# Template register map
Vendor: VendorName Co.Ltd; Series: SeriesName; File version: 1.2
CPU: CM7 r0p1, little endian, MPU, FPU, 4 interrupt priority bits
Registers are 32-bit, read-write, no defined reset value unless marked. A register's access mark holds for its fields unless they carry their own. Offsets are from the block's base; [hi:lo] are bit positions.

## CMPSS1 — Comparer Subsystem 1
Base 0x4001B000
Same registers: CMPSS2 0x4001B100, CMPSS3 0x4001B200, CMPSS4 0x4001B300, CMPSS5 0x4001B400, CMPSS6 0x4001B500, CMPSS7 0x4001B600, CMPSS8 0x4001B700
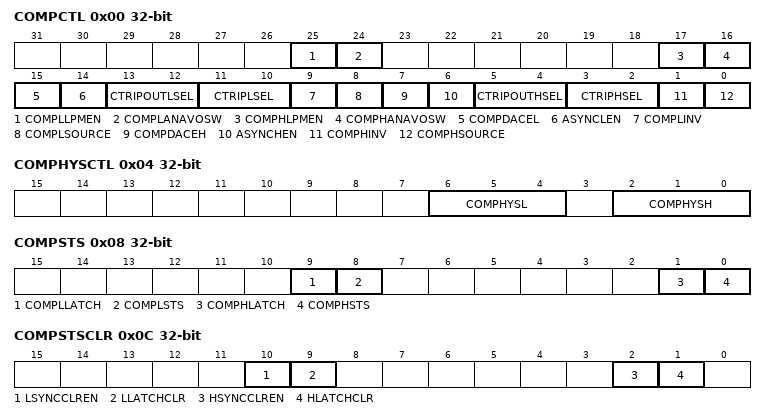
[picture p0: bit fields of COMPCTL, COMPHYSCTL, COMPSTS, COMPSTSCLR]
0x00 COMPCTL — CMPSS comparer control register
  [25] COMPLLPMEN — CMPSS COMPLLPMEN bit: low comparer low power consumption enable
  [24] COMPLANAVOSW — CMPSS COMPLANAVOSW bit: low comparer asynchronization output software control
  [17] COMPHLPMEN — CMPSS COMPHLPMEN bit: high comparer low power consumption enable
  [16] COMPHANAVOSW — CMPSS COMPHANAVOSW bit: high comparer asynchronization output software control
  [15] COMPDACEL — CMPSS COMPDACEL bit: low comparer DAC enable
  [14] ASYNCLEN — CMPSS ASYNCLEN bit: low comparer asynchronous path enable
  [13:12] CTRIPOUTLSEL — CMPSS CTRIPOUTLSEL[1:0] bit: low comparer CTRIPOUTL source select
  [11:10] CTRIPLSEL — CMPSS CTRIPLSEL[1:0] bit: low comparer CTRIPL select
  [9] COMPLINV — CMPSS COMPLINV bit: low comparer output reverse
  [8] COMPLSOURCE — CMPSS COMPLSOURCE bit: low comparer negative terminal input source select
  [7] COMPDACEH — CMPSS COMPDACEH bit: high comparer DAC enable
  [6] ASYNCHEN — CMPSS ASYNCHEN bit: high comparer asynchronous path enable
  [5:4] CTRIPOUTHSEL — CMPSS CTRIPOUTHSEL[1:0] bit: high comparer CTRIPOUTH source select
  [3:2] CTRIPHSEL — CMPSS CTRIPHSEL[1:0] bit: high comparer CTRIPH select
  [1] COMPHINV — CMPSS COMPHINV bit: high comparer output reverse
  [0] COMPHSOURCE — CMPSS COMPHSOURCE bit: high comparer negative terminal input source select
0x04 COMPHYSCTL — CMPSS comparer hysteresis control register
  [6:4] COMPHYSL — CMPSS COMPHYSL[2:0] bit: low comparer arrearage
  [2:0] COMPHYSH — CMPSS COMPHYSH[2:0] bit: high comparer arrearage
0x08 COMPSTS ro — CMPSS comparer status register
  [9] COMPLLATCH — CMPSS COMPLLATCH bit: low comparer digital filter latch output
  [8] COMPLSTS — CMPSS COMPLSTS bit: low comparer digital filter output
  [1] COMPHLATCH — CMPSS COMPHLATCH bit: high comparer digital filter latch output
  [0] COMPHSTS — CMPSS COMPHSTS bit: high comparer digital filter output
0x0C COMPSTSCLR — CMPSS comparer status clear register
  [10] LSYNCCLREN — CMPSS LSYNCCLREN bit: EPWMSYNCPER reset low comparer latch output
  [9] LLATCHCLR — CMPSS LLATCHCLR bit: low comparer latch output software clear 0
  [2] HSYNCCLREN — CMPSS HSYNCCLREN bit: EPWMSYNCPER reset high comparer latch output
  [1] HLATCHCLR — CMPSS HLATCHCLR bit: high comparer latch output software clear 0
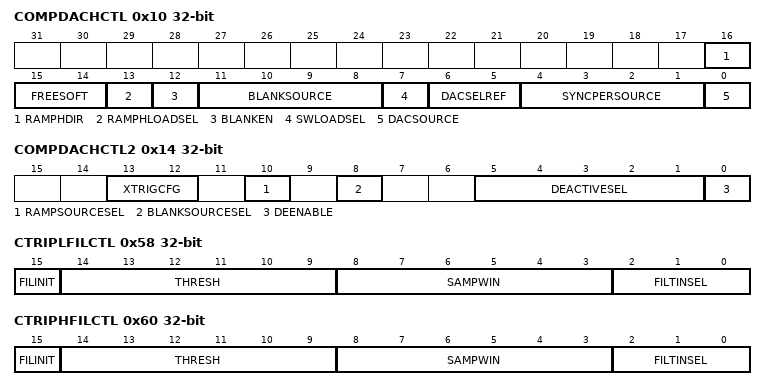
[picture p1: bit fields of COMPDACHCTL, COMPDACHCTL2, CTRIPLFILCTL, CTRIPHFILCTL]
0x10 COMPDACHCTL — CMPSS comparer high DAC control register
  [16] RAMPHDIR — CMPSS RAMPHDIR bit: high slope generator direction control bit
  [15:14] FREESOFT — CMPSS FREESOFT[1:0] bit: free-running operation or software operate simuation behavior
  [13] RAMPHLOADSEL — CMPSS RAMPHLOADSEL bit: slope generator loading select
  [12] BLANKEN — CMPSS BLANKEN bit: COMPH EPWMBLANK enable
  [11:8] BLANKSOURCE — CMPSS BLANKSOURCE[3:0] bit: COMPH EPWMBLANK source select
  [7] SWLOADSEL — CMPSS SWLOADSEL bit: DACxVALA update select bit
  [6:5] DACSELREF — CMPSS DACSELREF[1:0] bit: high or low DAC input reference voltage select
  [4:1] SYNCPERSOURCE — CMPSS SYNCPERSOURCE[3:0] bit: high slope generator source select
  [0] DACSOURCE — CMPSS DACSOURCE bit: DAC source select
0x14 COMPDACHCTL2 — CMPSS comparer high DAC control register2
  [13:12] XTRIGCFG — CMPSS XTRIGCFG[1:0] bit: slope generator cross-triggering configuration
  [10] RAMPSOURCESEL — CMPSS RAMPSOURCESEL bit: the RAMP source of RAMPH select
  [8] BLANKSOURCESEL — CMPSS BLANKSOURCESEL bit: the BLANK source of COMPH select
  [5:1] DEACTIVESEL — CMPSS DEACTIVESEL[4:0] bit: the selection of DEACTIVE source
  [0] DEENABLE — CMPSS DEENABLE bit: diode simulation mode enable
0x18 DACHVALS — CMPSS high DAC value shadow register
  [7:0] DACHVALS — CMPSS DACHVALS[7:0] bit: high DAC shadow register value
0x1C DACHVALA ro — CMPSS high DAC value valid register
  [7:0] DACHVALA — CMPSS DACHVALA[7:0] bit: high DAC valid value
0x20 RAMPHREFA ro — CMPSS high ramp reference valid register
  [11:0] RAMPHREFA — CMPSS RAMPHREFA[11:0] bit: slope generator reference value valid register
0x28 RAMPHREFS — CMPSS high ramp reference shadow register
  [11:0] RAMPHREFS — CMPSS RAMPHREFS[11:0] bit: slope generator reference value shadow register
0x30 RAMPHSTEPVALA ro — CMPSS high ramp step value valid register
  [11:0] RAMPHSTEPVALA — CMPSS RAMPHSTEPVALA[11:0] bit: high comparer slope stepping valid value
0x34 RAMPHCTLA ro — CMPSS high ramp control valid register
  [3:0] RAMPHCLKDIV — CMPSS RAMPHCLKDIV[3:0] bit: high comparer slope clock frequency divider valid value
0x38 RAMPHSTEPVALS — CMPSS high ramp step value shadow register
  [11:0] RAMPHSTEPVALS — CMPSS RAMPHSTEPVALS[11:0] bit: high comparer slope stepping shadow value
0x3C RAMPHCTLS — CMPSS high ramp control shadow register
  [3:0] RAMPHCLKDIV — CMPSS RAMPHCLKDIV[3:0] bit: high comparer slope clock frequency divider shadow value
0x40 RAMPHSTS ro — CMPSS high ramp status register
  [11:0] RAMPHVALUE — CMPSS RAMPHVALUE[11:0] bit: slope generator current value
0x44 RAMPHDLY2 — CMPSS high ramp delay shadow register2
  [15:0] RAMPHDLY2 — CMPSS RAMPHDLY2[15:0] bit: high slope generator delay value of register 2
0x48 DACLVALS — CMPSS low DAC value shadow register
  [7:0] DACLVALS — CMPSS DACLVALS[7:0] bit: low DAC shadow register value
0x4C DACLVALA ro — CMPSS low DAC value valid register
  [7:0] DACLVALA — CMPSS DACLVALA[7:0] bit: low comparer DAC valid value of register
0x50 RAMPHDLYA ro — CMPSS high ramp delay valid register
  [12:0] RAMPHDLYA — CMPSS RAMPHDLYA[12:0] bit: high slope generator delay valid value of register
0x54 RAMPHDLYS — CMPSS high ramp delay shadow register
  [12:0] RAMPHDLYS — CMPSS RAMPHDLYS[12:0] bit: high slope generator delay shadow register value
0x58 CTRIPLFILCTL — CMPSS low CTRIP filter control register
  [15] FILINIT — CMPSS FILINIT bit: low filter initialization
  [14:9] THRESH — CMPSS THRESH[5:0] bit: low filter sample threshold value
  [8:3] SAMPWIN — CMPSS SAMPWIN[5:0] bit: low filter sample window size
  [2:0] FILTINSEL — CMPSS FILTINSEL[2:0] bit: low filter input multipath select bit
0x5C CTRIPLFILCLKCTL — CMPSS low CTRIP filter clock control register
  [15:0] CLKPRESCALE — CMPSS CLKPRESCALE[15:0] bit: low filter sample clock prescale value
0x60 CTRIPHFILCTL — CMPSS high CTRIP filter control register
  [15] FILINIT — CMPSS FILINIT bit: high filter initialization
  [14:9] THRESH — CMPSS THRESH[5:0] bit: high filter sample threshold value
  [8:3] SAMPWIN — CMPSS SAMPWIN[5:0] bit: high filter sample window size
  [2:0] FILTINSEL — CMPSS FILTINSEL[2:0] bit: high filter input multipath select bit
0x64 CTRIPHFILCLKCTL — CMPSS high CTRIP filter clock control register
  [15:0] CLKPRESCALE — CMPSS CLKPRESCALE[15:0] bit: high filter sample clock prescale value
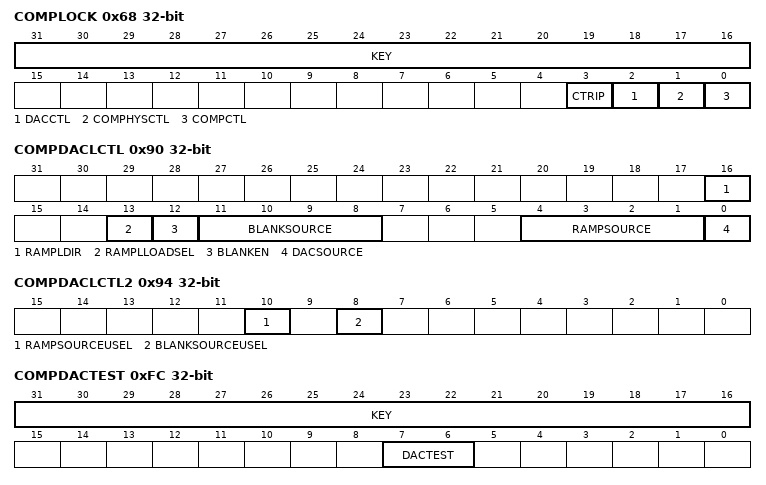
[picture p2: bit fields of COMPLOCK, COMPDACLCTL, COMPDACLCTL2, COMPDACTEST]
0x68 COMPLOCK — CMPSS comparer lock register
  [31:16] KEY wo — CMPSS KEY[15:0] bit: only when 0xA5A5 is written at high position can this register be written
  [3] CTRIP — CMPSS CTRIP bit: CTRIPxFILTCLKCTL* write-protection register bit
  [2] DACCTL — CMPSS DACCTL bit: COMPDACxCTL* write-protection register bit
  [1] COMPHYSCTL — CMPSS COMPHYSCTL bit: COMPHYSCTL write-protection register bit
  [0] COMPCTL — CMPSS COMPCTL bit: COMPCTL write-protection register bit
0x70 DACHVALS2 — CMPSS high DAC value shadow register2
  [7:0] DACHVALS2 — CMPSS DACHVALS2[7:0] bit: high DAC shadow value of register 2
0x74 DACLVALS2 — CMPSS low DAC value shadow register2
  [7:0] DACLVALS2 — CMPSS DACLVALS2[7:0] bit: low DAC shadow value of register 2
0x90 COMPDACLCTL — CMPSS comparer low DAC control register
  [16] RAMPLDIR — CMPSS RAMPLDIR bit: low slope generator direction control bit
  [13] RAMPLLOADSEL — CMPSS RAMPLLOADSEL bit: slope loading select
  [12] BLANKEN — CMPSS BLANKEN bit: COMPL EPWMBLANK enable
  [11:8] BLANKSOURCE — CMPSS BLANKSOURCE[3:0] bit: COMPL EPWMBLANK source select
  [4:1] RAMPSOURCE — CMPSS RAMPSOURCE[3:0] bit: COMPL EPWMSYNCPER source select
  [0] DACSOURCE — CMPSS DACSOURCE bit: DAC source select
0x94 COMPDACLCTL2 — CMPSS comparer low DAC control register2
  [10] RAMPSOURCEUSEL — CMPSS RAMPSOURCEUSEL bit: the RAMP source of RAMPL select
  [8] BLANKSOURCEUSEL — CMPSS BLANKSOURCEUSEL bit: the BLANK source of COMPL select
0xA0 RAMPLREFA ro — CMPSS low ramp reference valid register
  [11:0] RAMPLREFA — CMPSS RAMPLREFA[11:0] bit: slope generator largest reference valid register
0xA8 RAMPLREFS — CMPSS low ramp reference shadow register
  [11:0] RAMPLREFS — CMPSS RAMPLREFS[11:0] bit: low slope generator largest reference shadow register
0xB0 RAMPLSTEPVALA ro — CMPSS low ramp step value valid register
  [11:0] RAMPLSTEPVALA — CMPSS RAMPLSTEPVALA[11:0] bit: slope generator subtractor valid value
0xB4 RAMPLCTLA ro — CMPSS low ramp control valid register
  [3:0] RAMPLCLKDIV — CMPSS RAMPLCLKDIV[3:0] bit: low comparer slope clock frequency divider valid value
0xB8 RAMPLSTEPVALS — CMPSS low ramp step value shadow register
  [11:0] RAMPLSTEPVALS — CMPSS RAMPLSTEPVALS[11:0] bit: slope generator subtractor shadow register value
0xBC RAMPLCTLS — CMPSS low ramp step value shadow register
  [3:0] RAMPLCLKDIV — CMPSS RAMPLCLKDIV[3:0] bit: low slope clock frequency divider shadow value
0xC0 RAMPLSTS ro — CMPSS low ramp status register
  [11:0] RAMPLVALUE — CMPSS RAMPLVALUE[11:0] bit: low slope generator register current value
0xC4 RAMPLDLY2 — CMPSS low ramp delay register2
  [15:0] RAMPLDLY2 — CMPSS RAMPLDLY2[15:0] bit: low slope generator delay value of register 2
0xD0 RAMPLDLYA ro — CMPSS low ramp delay valid register
  [12:0] RAMPLDLYA — CMPSS RAMPLDLYA[12:0] bit: low slope generator delay valid value register
0xD4 RAMPLDLYS — CMPSS low ramp delay shadow register
  [12:0] RAMPLDLYS — CMPSS RAMPLDLYS[12:0] bit: low slope generator delay shadow register value
0xDC CTRIPLFILCLKCTL2 — CMPSS low CTRIP filter clock control register2
  [7:0] CLKPRESCALEU — CMPSS CLKPRESCALEU[7:0] bit: COMP low filter sample clock prescale high bit
0xE4 CTRIPHFILCLKCTL2 — CMPSS high CTRIP filter clock control register2
  [7:0] CLKPRESCALEU — CMPSS CLKPRESCALEU[7:0] bit: COMP high filter sample clock prescale high bit
0xFC COMPDACTEST — CMPSS comparer DAC test register
  [31:16] KEY wo — CMPSS KEY[15:0] bit: only when 0xA5A5 is written at high position can this register be written
  [7:6] DACTEST — CMPSS DACTEST[1:0] bit: comparer simulate debugging signal
